# STM32H7B0 register map
File version: 2.3
CPU: CM7 r0p1, little endian, MPU, FPU, 4 interrupt priority bits
Registers are 32-bit, read-write, reset 0x0 unless marked. A register's access mark holds for its fields unless they carry their own. Offsets are from the block's base; [hi:lo] are bit positions; {n}, {i} and the like mark numbered series; 'fields as' and 'values as' point back to an identical list.

## RCC (part 3 of 3) — Reset and clock control
Base 0x58024400
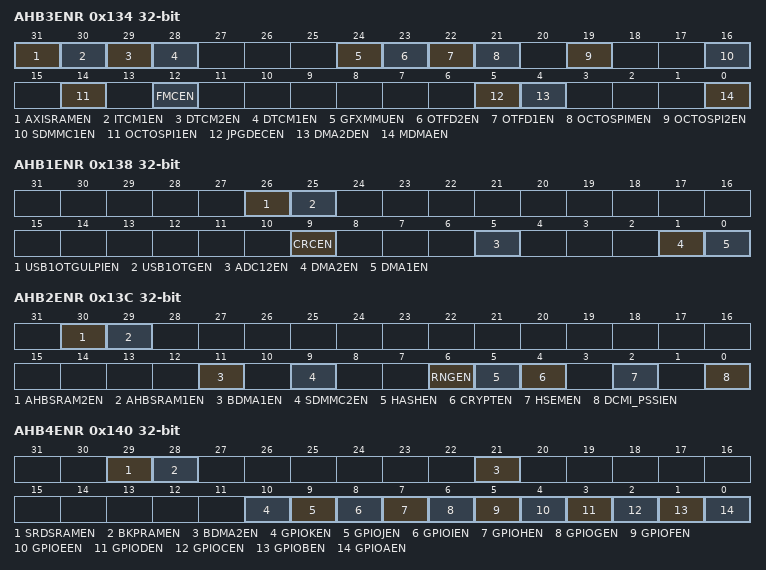
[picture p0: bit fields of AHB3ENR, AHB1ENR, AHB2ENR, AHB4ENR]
0x134 AHB3ENR access not given
  [all] fields
    0=Disabled (The selected clock is disabled); 1=Enabled (The selected clock is enabled)
  [31] AXISRAMEN — AXISRAM block enable
  [30] ITCM1EN — D1 ITCM block enable
  [29] DTCM2EN — D1 DTCM2 block enable
  [28] DTCM1EN — D1 DTCM1 block enable
  [24] GFXMMUEN rw — GFXMMU clock enable Set and reset by software.
  [23] OTFD2EN rw — OTFD2 clock enable Set and reset by software.
  [22] OTFD1EN rw — OTFD1 clock enable Set and reset by software.
  [21] OCTOSPIMEN rw — OCTOSPIM clock enable Set and reset by software.
  [19] OCTOSPI2EN rw — OCTOSPI2 clock enable Set and reset by software.
  [16] SDMMC1EN rw — SDMMC1 and SDMMC1 delay clock enable Set and reset by software.
  [14] OCTOSPI1EN rw — OCTOSPI1 and OCTOSPI1 delay clock enable Set and reset by software.
  [12] FMCEN rw — FMC peripheral clocks enable Set and reset by software. The peripheral clocks of the FMC are the kernel clock selected by FMCSEL and provided to fmc_ker_ck input, and the rcc_hclk3 bus interface clock.
  [5] JPGDECEN rw — JPGDEC peripheral clock enable Set and reset by software.
  [4] DMA2DEN rw — DMA2D peripheral clock enable Set and reset by software.
  [0] MDMAEN rw — MDMA peripheral clock enable Set and reset by software.
0x138 AHB1ENR
  [all] fields
    values as the fields of AHB3ENR
  [26] USB1OTGULPIEN — USB_PHY1 clocks enable Set and reset by software.
  [25] USB1OTGEN — USB1OTG peripheral clocks enable Set and reset by software. The peripheral clocks of the USB1OTG are the kernel clock selected by USBSEL and the rcc_hclk1 bus interface clock.
  [9] CRCEN — CRC peripheral clock enable Set and reset by software.
  [5] ADC12EN — ADC1 and 2 peripheral clocks enable Set and reset by software. The peripheral clocks of the ADC1 and 2 are the kernel clock selected by ADCSEL and provided to adc_ker_ck input, and the rcc_hclk1 bus interface clock.
  [1] DMA2EN — DMA2 clock enable Set and reset by software.
  [0] DMA1EN — DMA1 clock enable Set and reset by software.
0x13C AHB2ENR
  [all] fields
    values as the fields of AHB3ENR
  [30] AHBSRAM2EN — AHBSRAM2 block enable Set and reset by software. When set, this bit indicates that the SRAM2 is allocated by the CPU. It causes the CPU domain to take into account also the CPU operation modes, keeping the CPU domain in DRun when the CPU is in CRun.
  [29] AHBSRAM1EN — AHBSRAM1 block enable Set and reset by software. When set, this bit indicates that the SRAM1 is allocated by the CPU. It causes the CPU domain to take into account also the CPU operation modes, keeping the CPU domain in DRun when the CPU is in CRun.
  [11] BDMA1EN — DMA clock enable (DFSDM dedicated DMA) Set and reset by software.
  [9] SDMMC2EN — SDMMC2 and SDMMC2 delay clock enable Set and reset by software.
  [6] RNGEN — RNG peripheral clocks enable Set and reset by software. The peripheral clocks of the RNG are the kernel clock selected by RNGSEL and provided to rng_clk input, and the rcc_hclk2 bus interface clock.
  [5] HASHEN — HASH peripheral clock enable Set and reset by software.
  [4] CRYPTEN — CRYPT peripheral clock enable Set and reset by software.
  [2] HSEMEN — HSEM peripheral clock enable Set and reset by software.
  [0] DCMI_PSSIEN — digital camera interface peripheral clock enable (DCMI or PSSI depending which IP is active) Set and reset by software.
0x140 AHB4ENR
  [all] fields
    values as the fields of AHB3ENR
  [29] SRDSRAMEN — SmartRun domain SRAM clock enable Set and reset by software.
  [28] BKPRAMEN — Backup RAM clock enable Set and reset by software.
  [21] BDMA2EN — SmartRun domain DMA and DMAMUX clock enable Set and reset by software.
  [10] GPIOKEN — GPIOK peripheral clock enable Set and reset by software.
  [9] GPIOJEN — GPIOJ peripheral clock enable Set and reset by software.
  [8] GPIOIEN — GPIOI peripheral clock enable Set and reset by software.
  [7] GPIOHEN — GPIOH peripheral clock enable Set and reset by software.
  [6] GPIOGEN — GPIOG peripheral clock enable Set and reset by software.
  [5] GPIOFEN — GPIOF peripheral clock enable Set and reset by software.
  [4] GPIOEEN — GPIOE peripheral clock enable Set and reset by software.
  [3] GPIODEN — GPIOD peripheral clock enable Set and reset by software.
  [2] GPIOCEN — GPIOC peripheral clock enable Set and reset by software.
  [1] GPIOBEN — GPIOB peripheral clock enable Set and reset by software.
  [0] GPIOAEN — GPIOA peripheral clock enable Set and reset by software.
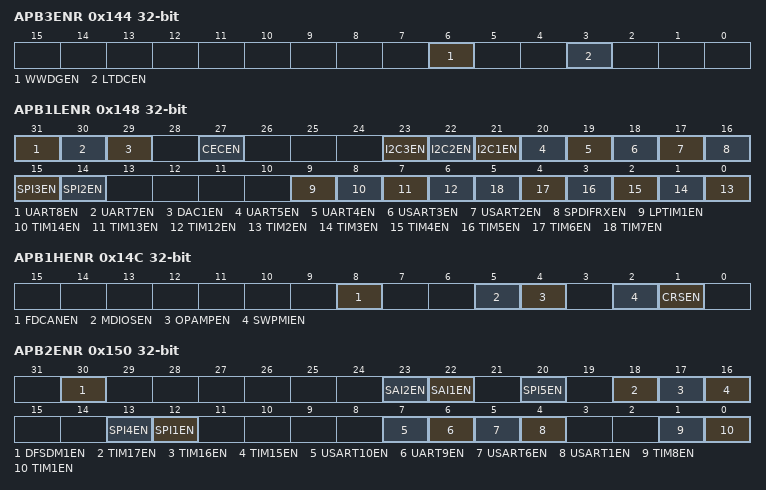
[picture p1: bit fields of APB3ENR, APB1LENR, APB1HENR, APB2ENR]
0x144 APB3ENR
  [6] WWDGEN — WWDG clock enable Set by software, and reset by hardware when a system reset occurs. Note that in order to work properly, before enabling the WWDG, the bit WW1RSC must be set to 1.
    values as the fields of AHB3ENR
  [3] LTDCEN — LTDC clock enable Provides the clock (ltdc_pclk, ltdc_aclk, ltdc_ker_ck) to the LTDC block. Set and reset by software.
    values as the fields of AHB3ENR
0x148 APB1LENR
  [all] fields
    values as the fields of AHB3ENR
  [31] UART8EN — UART8 peripheral clocks enable Set and reset by software. The peripheral clocks of the UART8 are the kernel clock selected by USART234578SEL and provided to usart_ker_ck input, and the rcc_pclk1 bus interface clock.
  [30] UART7EN — UART7 peripheral clocks enable Set and reset by software. The peripheral clocks of the UART7 are the kernel clock selected by USART234578SEL and provided to usart_ker_ck input, and the rcc_pclk1 bus interface clock.
  [29] DAC1EN — DAC1 (containing two converters) peripheral clock enable Set and reset by software.
  [27] CECEN — HDMI-CEC peripheral clock enable Set and reset by software. The peripheral clocks of the HDMI-CEC are the kernel clock selected by CECSEL and provided to cec_ker_ck input, and the rcc_pclk1 bus interface clock.
  [23] I2C3EN — I2C3 peripheral clocks enable Set and reset by software. The peripheral clocks of the I2C3 are the kernel clock selected by I2C123SEL and provided to i2C_ker_ck input, and the rcc_pclk1 bus interface clock.
  [22] I2C2EN — I2C2 peripheral clocks enable Set and reset by software. The peripheral clocks of the I2C2 are the kernel clock selected by I2C123SEL and provided to i2C_ker_ck input, and the rcc_pclk1 bus interface clock.
  [21] I2C1EN — I2C1 peripheral clocks enable Set and reset by software. The peripheral clocks of the I2C1 are the kernel clock selected by I2C123SEL and provided to i2C_ker_ck input, and the rcc_pclk1 bus interface clock.
  [20] UART5EN — UART5 peripheral clocks enable Set and reset by software. The peripheral clocks of the UART5 are the kernel clock selected by USART234578SEL and provided to usart_ker_ck input, and the rcc_pclk1 bus interface clock.
  [19] UART4EN — UART4 peripheral clocks enable Set and reset by software. The peripheral clocks of the UART4 are the kernel clock selected by USART234578SEL and provided to usart_ker_ck input, and the rcc_pclk1 bus interface clock.
  [18] USART3EN — USART3 peripheral clocks enable Set and reset by software. The peripheral clocks of the USART3 are the kernel clock selected by USART234578SEL and provided to usart_ker_ck input, and the rcc_pclk1 bus interface clock.
  [17] USART2EN — USART2peripheral clocks enable Set and reset by software. The peripheral clocks of the USART2 are the kernel clock selected by USART234578SEL and provided to usart_ker_ck input, and the rcc_pclk1 bus interface clock.
  [16] SPDIFRXEN — SPDIFRX peripheral clocks enable Set and reset by software. The peripheral clocks of the SPDIFRX are the kernel clock selected by SPDIFRXSEL and provided to spdifrx_ker_ck input, and the rcc_pclk1 bus interface clock.
  [15] SPI3EN — SPI3 peripheral clocks enable Set and reset by software. The peripheral clocks of the SPI3 are the kernel clock selected by I2S123SRC and provided to spi_ker_ck input, and the rcc_pclk1 bus interface clock.
  [14] SPI2EN — SPI2 peripheral clocks enable Set and reset by software. The peripheral clocks of the SPI2 are the kernel clock selected by I2S123SRC and provided to spi_ker_ck input, and the rcc_pclk1 bus interface clock.
  [9] LPTIM1EN — LPTIM1 peripheral clocks enable Set and reset by software. The peripheral clocks of the LPTIM1 are the kernel clock selected by LPTIM1SEL and provided to lptim_ker_ck input, and the rcc_pclk1 bus interface clock.
  [8] TIM14EN — TIM14 peripheral clock enable Set and reset by software.
  [7] TIM13EN — TIM13 peripheral clock enable Set and reset by software.
  [6] TIM12EN — TIM12 peripheral clock enable Set and reset by software.
  [n-2] TIM{n}EN (n=2..7) — TIM{n} peripheral clock enable Set and reset by software.
0x14C APB1HENR
  [all] fields
    values as the fields of AHB3ENR
  [8] FDCANEN — FDCAN peripheral clocks enable Set and reset by software. The peripheral clocks of the FDCAN are the kernel clock selected by FDCANSEL and provided to fdcan_ker_ck input, and the rcc_pclk1 bus interface clock.
  [5] MDIOSEN — MDIOS peripheral clock enable Set and reset by software.
  [4] OPAMPEN — OPAMP peripheral clock enable Set and reset by software.
  [2] SWPMIEN — SWPMI peripheral clocks enable Set and reset by software.
  [1] CRSEN — clock recovery system peripheral clock enable Set and reset by software.
0x150 APB2ENR
  [all] fields
    values as the fields of AHB3ENR
  [30] DFSDM1EN — DFSDM1 peripheral clocks enable Set and reset by software. DFSDM1 peripheral clocks are the kernel clocks selected by SAI1SEL and DFSDM1SEL and provided to Aclk and clk inputs respectively,
  [23] SAI2EN — SAI2 peripheral clocks enable Set and reset by software. The peripheral clocks of the SAI2 are the kernel clock selected by SAI2SEL and provided to sai_a_ker_ck and sai_b_ker_ck inputs, and the rcc_pclk2 bus interface clock.
  [22] SAI1EN — SAI1 peripheral clocks enable Set and reset by software. The peripheral clocks of the SAI1 are: the kernel clock selected by SAI1SEL and provided to sai_a_ker_ck and sai_b_ker_ck inputs, and the rcc_pclk2 bus interface clock.
  [20] SPI5EN — SPI5 peripheral clocks enable Set and reset by software. The peripheral clocks of the SPI5 are the kernel clock selected by SPI45SEL and provided to spi_ker_ck input, and the rcc_pclk2 bus interface clock.
  [18] TIM17EN — TIM17 peripheral clock enable Set and reset by software.
  [17] TIM16EN — TIM16 peripheral clock enable Set and reset by software.
  [16] TIM15EN — TIM15 peripheral clock enable Set and reset by software.
  [13] SPI4EN — SPI4 Peripheral Clocks Enable Set and reset by software. The peripheral clocks of the SPI4 are: the kernel clock selected by SPI45SEL and provided to spi_ker_ck input, and the rcc_pclk2 bus interface clock.
  [12] SPI1EN — SPI1 Peripheral Clocks Enable Set and reset by software. The peripheral clocks of the SPI1 are: the kernel clock selected by I2S123SRC and provided to spi_ker_ck input, and the rcc_pclk2 bus interface clock.
  [7] USART10EN — USART10 peripheral clocks enable Set and reset by software. The peripheral clocks of the USART10 are the kernel clock selected by USART16910SEL and provided to UCKL input, and the rcc_pclk2 bus interface clock.
  [6] UART9EN — UART9 peripheral clocks enable Set and reset by software. The peripheral clocks of the UART9 are the kernel clock selected by USART16910SEL and provided to UCKL input, and the rcc_pclk2 bus interface clock.
  [5] USART6EN — USART6 peripheral clocks enable Set and reset by software. The peripheral clocks of the USART6 are the kernel clock selected by USART16910SEL and provided to UCKL input, and the rcc_pclk2 bus interface clock.
  [4] USART1EN — USART1 peripheral clocks enable Set and reset by software. The peripheral clocks of the USART1 are the kernel clock selected by USART16910SEL and provided to UCKL input, and the rcc_pclk2 bus interface clock.
  [1] TIM8EN — TIM8 peripheral clock enable Set and reset by software.
  [0] TIM1EN — TIM1 peripheral clock enable Set and reset by software.
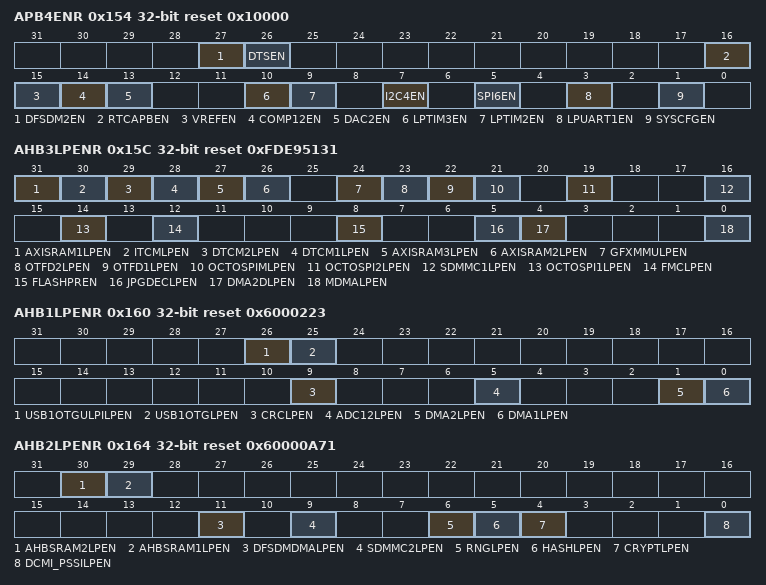
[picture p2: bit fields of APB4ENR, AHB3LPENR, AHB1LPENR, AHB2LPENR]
0x154 APB4ENR reset 0x10000
  [all] fields
    values as the fields of AHB3ENR
  [27] DFSDM2EN — DFSDM2peripheral clock enable Set and reset by software.
  [26] DTSEN — Digital temperature sensor peripheral clock enable Set and reset by software.
  [16] RTCAPBEN — RTC APB clock enable Set and reset by software.
  [15] VREFEN — VREF peripheral clock enable Set and reset by software.
  [14] COMP12EN — COMP1 and 2 peripheral clock enable Set and reset by software.
  [13] DAC2EN — DAC2 (containing one converter) peripheral clock enable Set and reset by software.
  [10] LPTIM3EN — LPTIM3 peripheral clocks enable Set and reset by software. The peripheral clocks of the LPTIM3 are the kernel clock selected by LPTIM345SEL and provided to lptim_ker_ck input, and the rcc_pclk4 bus interface clock.
  [9] LPTIM2EN — LPTIM2 peripheral clocks enable Set and reset by software. The peripheral clocks of the LPTIM2 are the kernel clock selected by LPTIM2SEL and provided to lptim_ker_ck input, and the rcc_pclk4 bus interface clock.
  [7] I2C4EN — I2C4 peripheral clocks enable Set and reset by software. The peripheral clocks of the I2C4 are the kernel clock selected by I2C4SEL and provided to i2C_ker_ck input, and the rcc_pclk4 bus interface clock.
  [5] SPI6EN — SPI6 peripheral clocks enable Set and reset by software. The peripheral clocks of the SPI6 are the kernel clock selected by SPI6SEL and provided to spi_ker_ck input, and the rcc_pclk4 bus interface clock.
  [3] LPUART1EN — LPUART1 peripheral clocks enable Set and reset by software. The peripheral clocks of the LPUART1 are the kernel clock selected by LPUART1SEL and provided to lpuart_ker_ck input, and the rcc_pclk4 bus interface clock.
  [1] SYSCFGEN — SYSCFG peripheral clock enable Set and reset by software.
0x15C AHB3LPENR reset 0xFDE95131
  [31] AXISRAM1LPEN — AXISRAM1 block clock enable during CSleep mode Set and reset by software.
    0=Disabled (The selected clock is disabled during csleep mode); 1=Enabled (The selected clock is enabled during csleep mode)
  [30] ITCMLPEN — ITCM block clock enable during CSleep mode Set and reset by software.
    values as AXISRAM1LPEN
  [29] DTCM2LPEN — DTCM2 block clock enable during CSleep mode Set and reset by software.
    values as AXISRAM1LPEN
  [28] DTCM1LPEN — DTCM1 block clock enable during CSleep mode Set and reset by software.
    values as AXISRAM1LPEN
  [27] AXISRAM3LPEN — AXISRAM3 block clock enable during CSleep mode Set and reset by software.
    values as AXISRAM1LPEN
  [26] AXISRAM2LPEN — AXISRAM2 block clock enable during CSleep mode Set and reset by software.
    values as AXISRAM1LPEN
  [24] GFXMMULPEN — GFXMMU block clock enable during CSleep mode Set and reset by software.
    values as AXISRAM1LPEN
  [23] OTFD2LPEN — OTFD2 block clock enable during CSleep mode Set and reset by software.
    values as AXISRAM1LPEN
  [22] OTFD1LPEN — OTFD1 block clock enable during CSleep mode Set and reset by software.
    values as AXISRAM1LPEN
  [21] OCTOSPIMLPEN — OCTOSPIM block clock enable during CSleep mode Set and reset by software.
    values as AXISRAM1LPEN
  [19] OCTOSPI2LPEN — OCTOSPI2 and OCTOSPI2 delay clock enable during CSleep mode Set and reset by software.
    values as AXISRAM1LPEN
  [16] SDMMC1LPEN — SDMMC1 and SDMMC1 delay clock enable during CSleep mode Set and reset by software.
    values as AXISRAM1LPEN
  [14] OCTOSPI1LPEN — OCTOSPI1 and OCTOSPI1 delay clock enable during CSleep mode Set and reset by software.
    values as AXISRAM1LPEN
  [12] FMCLPEN — FMC peripheral clocks enable during CSleep mode Set and reset by software. The peripheral clocks of the FMC are the kernel clock selected by FMCSEL and provided to fmc_ker_ck input, and the rcc_hclk3 bus interface clock.
    values as AXISRAM1LPEN
  [8] FLASHPREN — Flash interface clock enable during csleep mode
  [5] JPGDECLPEN — JPGDEC clock enable during CSleep mode Set and reset by software.
    values as AXISRAM1LPEN
  [4] DMA2DLPEN — DMA2D clock enable during CSleep mode Set and reset by software.
    values as AXISRAM1LPEN
  [0] MDMALPEN — MDMA clock enable during CSleep mode Set and reset by software.
    values as AXISRAM1LPEN
0x160 AHB1LPENR reset 0x6000223
  [all] fields
    values as AHB3LPENR.AXISRAM1LPEN
  [26] USB1OTGULPILPEN — USB_PHY1 clock enable during CSleep mode Set and reset by software.
  [25] USB1OTGLPEN — USB1OTG peripheral clock enable during CSleep mode Set and reset by software. The peripheral clocks of the USB1OTG are the kernel clock selected by USBSEL and the rcc_hclk1 bus interface clock.
  [9] CRCLPEN — CRC peripheral clock enable during CSleep mode Set and reset by software.
  [5] ADC12LPEN — ADC1 and 2 peripheral clocks enable during CSleep mode Set and reset by software. The peripheral clocks of the ADC1 and 2 are the kernel clock selected by ADCSEL and provided to adc_ker_ck input, and the rcc_hclk1 bus interface clock.
  [1] DMA2LPEN — DMA2 clock enable during CSleep mode Set and reset by software.
  [0] DMA1LPEN — DMA1 clock enable during CSleep mode Set and reset by software.
0x164 AHB2LPENR reset 0x60000A71
  [all] fields
    values as AHB3LPENR.AXISRAM1LPEN
  [30] AHBSRAM2LPEN — AHBSRAM2 clock enable during CSleep mode Set and reset by software.
  [29] AHBSRAM1LPEN — AHBSRAM1 clock enable during CSleep mode Set and reset by software.
  [11] DFSDMDMALPEN — DFSDMDMA clock enable during CSleep mode Set and reset by software.
  [9] SDMMC2LPEN — SDMMC2 and SDMMC2 delay clock enable during CSleep mode Set and reset by software.
  [6] RNGLPEN — RNG peripheral clock enable during CSleep mode Set and reset by software. The peripheral clocks of the RNG are the kernel clock selected by RNGSEL and provided to rng_clk input, and the rcc_hclk2 bus interface clock.
  [5] HASHLPEN — HASH peripheral clock enable during CSleep mode Set and reset by software.
  [4] CRYPTLPEN — CRYPT peripheral clock enable during CSleep mode Set and reset by software.
  [0] DCMI_PSSILPEN — digital camera interface peripheral clock enable during CSleep mode (DCMI or PSSI depending which IP is active) Set and reset by software.
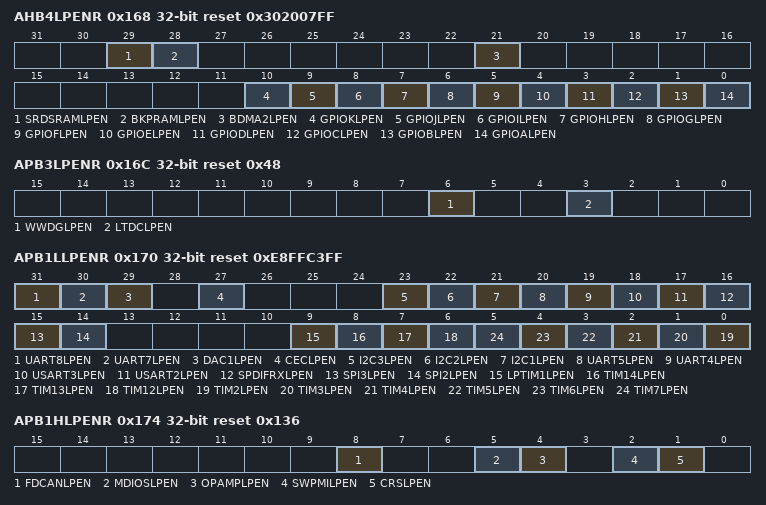
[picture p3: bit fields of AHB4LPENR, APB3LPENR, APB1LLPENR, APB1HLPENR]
0x168 AHB4LPENR reset 0x302007FF
  [all] fields
    values as AHB3LPENR.AXISRAM1LPEN
  [29] SRDSRAMLPEN — SmartRun domain SRAM clock enable during CSleep mode Set and reset by software.
  [28] BKPRAMLPEN — Backup RAM clock enable during CSleep mode Set and reset by software.
  [21] BDMA2LPEN — SmartRun domain DMA and DMAMUX clock enable during CSleep mode Set and reset by software.
  [10] GPIOKLPEN — GPIOK peripheral clock enable during CSleep mode Set and reset by software.
  [9] GPIOJLPEN — GPIOJ peripheral clock enable during CSleep mode Set and reset by software.
  [8] GPIOILPEN — GPIOI peripheral clock enable during CSleep mode Set and reset by software.
  [7] GPIOHLPEN — GPIOH peripheral clock enable during CSleep mode Set and reset by software.
  [6] GPIOGLPEN — GPIOG peripheral clock enable during CSleep mode Set and reset by software.
  [5] GPIOFLPEN — GPIOF peripheral clock enable during CSleep mode Set and reset by software.
  [4] GPIOELPEN — GPIOE peripheral clock enable during CSleep mode Set and reset by software.
  [3] GPIODLPEN — GPIOD peripheral clock enable during CSleep mode Set and reset by software.
  [2] GPIOCLPEN — GPIOC peripheral clock enable during CSleep mode Set and reset by software.
  [1] GPIOBLPEN — GPIOB peripheral clock enable during CSleep mode Set and reset by software.
  [0] GPIOALPEN — GPIOA peripheral clock enable during CSleep mode Set and reset by software.
0x16C APB3LPENR reset 0x48
  [6] WWDGLPEN — WWDG clock enable during CSleep mode Set and reset by software.
    values as AHB3LPENR.AXISRAM1LPEN
  [3] LTDCLPEN — LTDC peripheral clock enable during CSleep mode Set and reset by software. The LTDC peripheral clocks are the kernel clock provided to ltdc_ker_ck input and the rcc_pclk3 bus interface clock.
    values as AHB3LPENR.AXISRAM1LPEN
0x170 APB1LLPENR reset 0xE8FFC3FF
  [all] fields
    values as AHB3LPENR.AXISRAM1LPEN
  [31] UART8LPEN — UART8 peripheral clocks enable during CSleep mode Set and reset by software. The peripheral clocks of the UART8 are the kernel clock selected by USART234578SEL and provided to usart_ker_ck input, and the rcc_pclk1 bus interface clock.
  [30] UART7LPEN — UART7 peripheral clocks enable during CSleep mode Set and reset by software. The peripheral clocks of the UART7 are the kernel clock selected by USART234578SEL and provided to usart_ker_ck input, and the rcc_pclk1 bus interface clock.
  [29] DAC1LPEN — DAC1 (containing two converters) peripheral clock enable during CSleep mode Set and reset by software.
  [27] CECLPEN — HDMI-CEC peripheral clocks enable during CSleep mode Set and reset by software. The peripheral clocks of the HDMI-CEC are the kernel clock selected by CECSEL and provided to cec_ker_ck input, and the rcc_pclk1 bus interface clock.
  [23] I2C3LPEN — I2C3 peripheral clocks enable during CSleep mode Set and reset by software. The peripheral clocks of the I2C3 are the kernel clock selected by I2C123SEL and provided to i2C_ker_ck input, and the rcc_pclk1 bus interface clock.
  [22] I2C2LPEN — I2C2 peripheral clocks enable during CSleep mode Set and reset by software. The peripheral clocks of the I2C2 are the kernel clock selected by I2C123SEL and provided to i2C_ker_ck input, and the rcc_pclk1 bus interface clock.
  [21] I2C1LPEN — I2C1 peripheral clocks enable during CSleep mode Set and reset by software. The peripheral clocks of the I2C1 are the kernel clock selected by I2C123SEL and provided to i2C_ker_ck input, and the rcc_pclk1 bus interface clock.
  [20] UART5LPEN — UART5 peripheral clocks enable during CSleep mode Set and reset by software. The peripheral clocks of the UART5 are the kernel clock selected by USART234578SEL and provided to usart_ker_ck input, and the rcc_pclk1 bus interface clock.
  [19] UART4LPEN — UART4 peripheral clocks enable during CSleep mode Set and reset by software. The peripheral clocks of the UART4 are the kernel clock selected by USART234578SEL and provided to usart_ker_ck input, and the rcc_pclk1 bus interface clock.
  [18] USART3LPEN — USART3 peripheral clocks enable during CSleep mode Set and reset by software. The peripheral clocks of the USART3 are the kernel clock selected by USART234578SEL and provided to usart_ker_ck input, and the rcc_pclk1 bus interface clock.
  [17] USART2LPEN — USART2 peripheral clocks enable during CSleep mode Set and reset by software. The peripheral clocks of the USART2 are the kernel clock selected by USART234578SEL and provided to usart_ker_ck input, and the rcc_pclk1 bus interface clock.
  [16] SPDIFRXLPEN — SPDIFRX peripheral clocks enable during CSleep mode Set and reset by software. The peripheral clocks of the SPDIFRX are: the kernel clock selected by SPDIFRXSEL and provided to spdifrx_ker_ck input, and the rcc_pclk1 bus interface clock.
  [15] SPI3LPEN — SPI3 peripheral clocks enable during CSleep mode Set and reset by software. The peripheral clocks of the SPI3 are the kernel clock selected by I2S123SRC and provided to spi_ker_ck input, and the rcc_pclk1 bus interface clock.
  [14] SPI2LPEN — SPI2 peripheral clocks enable during CSleep mode Set and reset by software. The peripheral clocks of the SPI2 are the kernel clock selected by I2S123SRC and provided to spi_ker_ck input, and the rcc_pclk1 bus interface clock.
  [9] LPTIM1LPEN — LPTIM1 peripheral clocks enable during CSleep mode Set and reset by software. The peripheral clocks of the LPTIM1 are the kernel clock selected by LPTIM1SEL and provided to lptim_ker_ck input, and the rcc_pclk1 bus interface clock.
  [8] TIM14LPEN — TIM14 peripheral clock enable during CSleep mode Set and reset by software.
  [7] TIM13LPEN — TIM13 peripheral clock enable during CSleep mode Set and reset by software.
  [6] TIM12LPEN — TIM12 peripheral clock enable during CSleep mode Set and reset by software.
  [n-2] TIM{n}LPEN (n=2..7) — TIM{n} peripheral clock enable during CSleep mode Set and reset by software.
0x174 APB1HLPENR reset 0x136
  [all] fields
    values as AHB3LPENR.AXISRAM1LPEN
  [8] FDCANLPEN — FDCAN peripheral clocks enable during CSleep mode Set and reset by software. The peripheral clocks of the FDCAN are: the kernel clock selected by FDCANSEL and provided to fdcan_clk input, and the rcc_pclk1 bus interface clock.
  [5] MDIOSLPEN — MDIOS peripheral clock enable during CSleep mode Set and reset by software.
  [4] OPAMPLPEN — OPAMP peripheral clock enable during CSleep mode Set and reset by software.
  [2] SWPMILPEN — SWPMI peripheral clocks enable during CSleep mode Set and reset by software. The peripheral clocks of the SWPMI are the kernel clock selected by SWPMISEL and provided to swpmi_ker_ck input, and the rcc_pclk1 bus interface clock.
  [1] CRSLPEN — clock recovery system peripheral clock enable during CSleep mode Set and reset by software.
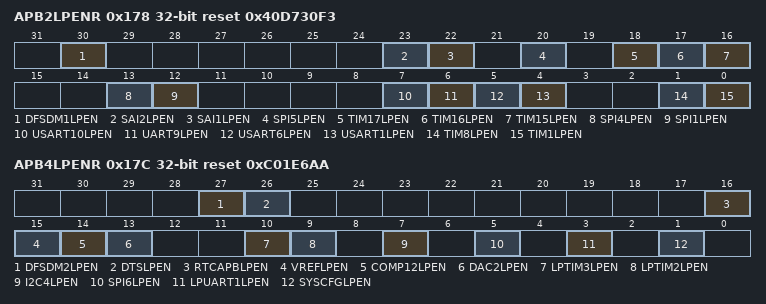
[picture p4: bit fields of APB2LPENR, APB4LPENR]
0x178 APB2LPENR reset 0x40D730F3
  [all] fields
    values as AHB3LPENR.AXISRAM1LPEN
  [30] DFSDM1LPEN — DFSDM1 peripheral clocks enable during CSleep mode Set and reset by software. DFSDM1 peripheral clocks are the kernel clocks selected by SAI1SEL and DFSDM1SEL and provided to Aclk and clk inputs respectively, and the rcc_pclk2 bus interface clock.
  [23] SAI2LPEN — SAI2 peripheral clocks enable during CSleep mode Set and reset by software. The peripheral clocks of the SAI2 are the kernel clock selected by SAI23EL and provided to sai_a_ker_ck and sai_b_ker_ck inputs, and the rcc_pclk2 bus interface clock.
  [22] SAI1LPEN — SAI1 peripheral clocks enable during CSleep mode Set and reset by software. The peripheral clocks of the SAI1 are: the kernel clock selected by SAI1SEL and provided to sai_a_ker_ck and sai_b_ker_ck inputs, and the rcc_pclk2 bus interface clock.
  [20] SPI5LPEN — SPI5 peripheral clocks enable during CSleep mode Set and reset by software. The peripheral clocks of the SPI5 are the kernel clock selected by SPI45SEL and provided to spi_ker_ck input, and the rcc_pclk2 bus interface clock.
  [18] TIM17LPEN — TIM17 peripheral clock enable during CSleep mode Set and reset by software.
  [17] TIM16LPEN — TIM16 peripheral clock enable during CSleep mode Set and reset by software.
  [16] TIM15LPEN — TIM15 peripheral clock enable during CSleep mode Set and reset by software.
  [13] SPI4LPEN — SPI4 peripheral clock enable during CSleep mode Set and reset by software. The peripheral clocks of the SPI4 are: the kernel clock selected by SPI45SEL and provided to spi_ker_ck input, and the rcc_pclk2 bus interface clock.
  [12] SPI1LPEN — SPI1 peripheral clock enable during CSleep mode Set and reset by software. The peripheral clocks of the SPI1 are: the kernel clock selected by I2S123SRC and provided to spi_ker_ck input, and the rcc_pclk2 bus interface clock.
  [7] USART10LPEN — USART10 peripheral clock enable during CSleep mode Set and reset by software. The peripheral clocks of the USART10 are the kernel clock selected by USART16910SEL and provided to usart_ker_ck input, and the rcc_pclk2 bus interface clock.
  [6] UART9LPEN — UART9 peripheral clock enable during CSleep mode Set and reset by software. The peripheral clocks of the UART9 are the kernel clock selected by USART16910SEL and provided to usart_ker_ck input, and the rcc_pclk2 bus interface clock.
  [5] USART6LPEN — USART6 peripheral clock enable during CSleep mode Set and reset by software. The peripheral clocks of the USART6 are the kernel clock selected by USART16910SEL and provided to usart_ker_ck input, and the rcc_pclk2 bus interface clock.
  [4] USART1LPEN — USART1 peripheral clock enable during CSleep mode Set and reset by software. The peripheral clocks of the USART1 are the kernel clock selected by USART16910SEL and provided to usart_ker_ck inputs, and the rcc_pclk2 bus interface clock.
  [1] TIM8LPEN — TIM8 peripheral clock enable during CSleep mode Set and reset by software.
  [0] TIM1LPEN — TIM1 peripheral clock enable during CSleep mode Set and reset by software.
0x17C APB4LPENR reset 0xC01E6AA
  [all] fields
    values as AHB3LPENR.AXISRAM1LPEN
  [27] DFSDM2LPEN — DFSDM2 peripheral clock enable during CSleep mode Set and reset by software.
  [26] DTSLPEN — temperature sensor peripheral clock enable during CSleep mode Set and reset by software.
  [16] RTCAPBLPEN — RTC APB clock enable during CSleep mode Set and reset by software.
  [15] VREFLPEN — VREF peripheral clock enable during CSleep mode Set and reset by software.
  [14] COMP12LPEN — COMP1 and 2 peripheral clock enable during CSleep mode Set and reset by software.
  [13] DAC2LPEN — DAC2 (containing one converter) peripheral clock enable during CSleep mode Set and reset by software.
  [10] LPTIM3LPEN — LPTIM3 peripheral clocks enable during CSleep mode Set and reset by software. The peripheral clocks of the LPTIM3 are the kernel clock selected by LPTIM345SEL and provided to lptim_ker_ck input, and the rcc_pclk4 bus interface clock.
  [9] LPTIM2LPEN — LPTIM2 peripheral clocks enable during CSleep mode Set and reset by software. The peripheral clocks of the LPTIM2 are the kernel clock selected by LPTIM2SEL and provided to lptim_ker_ck input, and the rcc_pclk4 bus interface clock.
  [7] I2C4LPEN — I2C4 peripheral clocks enable during CSleep mode Set and reset by software. The peripheral clocks of the I2C4 are the kernel clock selected by I2C4SEL and provided to i2C_ker_ck input, and the rcc_pclk4 bus interface clock.
  [5] SPI6LPEN — SPI6 peripheral clocks enable during CSleep mode Set and reset by software. The peripheral clocks of the SPI6 are the kernel clock selected by SPI6SEL and provided to com_ck input, and the rcc_pclk4 bus interface clock.
  [3] LPUART1LPEN — LPUART1 peripheral clocks enable during CSleep mode Set and reset by software. The peripheral clocks of the LPUART1 are the kernel clock selected by LPUART1SEL and provided to lpuart_ker_ck input, and the rcc_pclk4 bus interface clock.
  [1] SYSCFGLPEN — SYSCFG peripheral clock enable during CSleep mode Set and reset by software.
